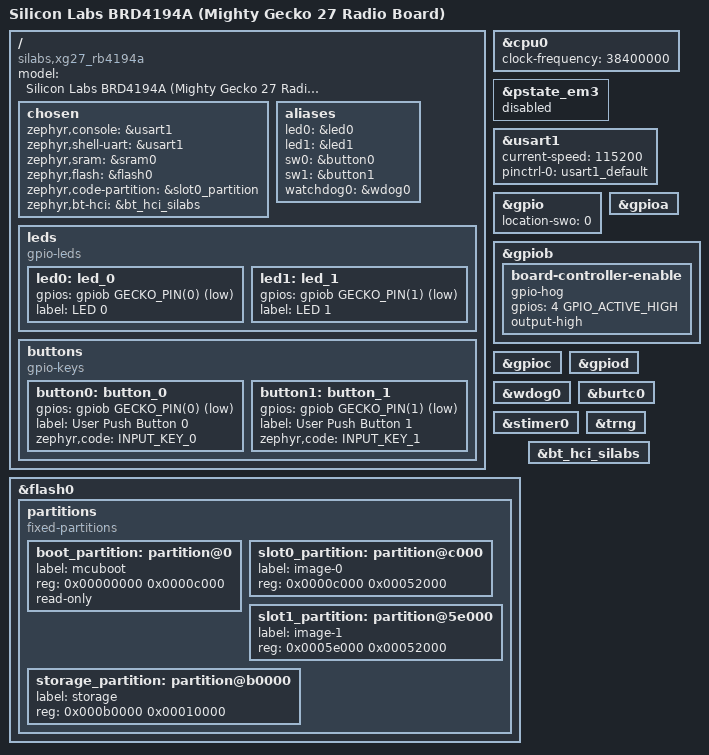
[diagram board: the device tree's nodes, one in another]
/*
 * Copyright (c) 2024 EMEA Central FAEs
 *
 * SPDX-License-Identifier: Apache-2.0
 */

/dts-v1/;
#include <silabs/efr32bg27.dtsi>
#include <zephyr/dt-bindings/input/input-event-codes.h>
#include "xg27_rb4194a-pinctrl.dtsi"

/ {
	model = "Silicon Labs BRD4194A (Mighty Gecko 27 Radio Board)";
	compatible = "silabs,xg27_rb4194a", "silabs,efr32bg27";

	chosen {
		zephyr,console = &usart1;
		zephyr,shell-uart = &usart1;
		zephyr,sram = &sram0;
		zephyr,flash = &flash0;
		zephyr,code-partition = &slot0_partition;
		zephyr,bt-hci = &bt_hci_silabs;
	};

	/* These aliases are provided for compatibility with samples */
	aliases {
		led0 = &led0;
		led1 = &led1;
		sw0 = &button0;
		sw1 = &button1;
		watchdog0 = &wdog0;
	};

	leds {
		compatible = "gpio-leds";
		led0: led_0 {
			gpios = <&gpiob GECKO_PIN(0) GPIO_ACTIVE_LOW>;
			label = "LED 0";
		};
		led1: led_1 {
			gpios = <&gpiob GECKO_PIN(1) GPIO_ACTIVE_LOW>;
			label = "LED 1";
		};
	};

	buttons {
		compatible = "gpio-keys";
		button0: button_0 {
			gpios = <&gpiob GECKO_PIN(0) GPIO_ACTIVE_LOW>;
			label = "User Push Button 0";
			zephyr,code = <INPUT_KEY_0>;
		};
		button1: button_1 {
			gpios = <&gpiob GECKO_PIN(1) GPIO_ACTIVE_LOW>;
			label = "User Push Button 1";
			zephyr,code = <INPUT_KEY_1>;
		};
	};
};

&cpu0 {
	clock-frequency = <38400000>;
};

&pstate_em3 {
	status = "disabled";
};

&usart1 {
	current-speed = <115200>;
	pinctrl-0 = <&usart1_default>;
	pinctrl-names = "default";
	status = "okay";
};

&gpio {
	location-swo = <0>;
	status = "okay";
};

&gpioa {
	status = "okay";
};

&gpiob {
	status = "okay";

	board-controller-enable {
		gpio-hog;
		gpios = <4 GPIO_ACTIVE_HIGH>;
		output-high;
	};
};

&gpioc {
	status = "okay";
};

&gpiod {
	status = "okay";
};

&wdog0 {
	status = "okay";
};

&burtc0 {
	status = "okay";
};

&stimer0 {
	status = "okay";
};

&trng {
	status = "okay";
};

&flash0 {
	partitions {
		compatible = "fixed-partitions";
		#address-cells = <1>;
		#size-cells = <1>;

		/* Reserve 48 KiB for the bootloader */
		boot_partition: partition@0 {
			label = "mcuboot";
			reg = <0x00000000 0x0000c000>;
			read-only;
		};

		/* Reserve 328 KiB for the application in slot 0 */
		slot0_partition: partition@c000 {
			label = "image-0";
			reg = <0x0000c000 0x00052000>;
		};

		/* Reserve 328 KiB for the application in slot 1 */
		slot1_partition: partition@5e000 {
			label = "image-1";
			reg = <0x0005e000 0x00052000>;
		};

		/* Set 64 KiB of storage at the end of the 768 KiB of flash */
		storage_partition: partition@b0000 {
			label = "storage";
			reg = <0x000b0000 0x00010000>;
		};
	};
};

&bt_hci_silabs {
	status = "okay";
};
